# LargeDummyDevice register map
File version: 1.0
Registers are 32-bit, read-write, no defined reset value unless marked. A register's access mark holds for its fields unless they carry their own. Offsets are from the block's base; [hi:lo] are bit positions.

## PERIPHERAL_77
Base 0x4004C000
0x04 REG_1 — Register 1
  [32:30] FIELD_4, [32:30] FIELD_14, [29] FIELD_2, [31:29] FIELD_11, [26:25] FIELD_19, [24:22] FIELD_3, [22] FIELD_21, [23:21] FIELD_6, [18:15] FIELD_13, [16:14] FIELD_15, [13] FIELD_5, [14:13] FIELD_9, [14:11] FIELD_18, [11:10] FIELD_25, [13:9] FIELD_7, [12:9] FIELD_23, [9:8] FIELD_16, [11:7] FIELD_12, [7] FIELD_20, [9:6] FIELD_8, [6:5] FIELD_17, [7:4] FIELD_1, [7:3] FIELD_24, [2:1] FIELD_22, [0] FIELD_10
0x08 REG_2 — Register 2
  [9] FIELD_1
0x0C REG_3 — Register 3
  [33:31] FIELD_2, [30] FIELD_21, [31:29] FIELD_15, [29:28] FIELD_26, [31:27] FIELD_20, [26] FIELD_4, [26:24] FIELD_16, [23] FIELD_14, [23] FIELD_17, [23:19] FIELD_18, [16:14] FIELD_5, [15:13] FIELD_12, [13] FIELD_25, [16:12] FIELD_6, [14:12] FIELD_27, [16:12] FIELD_30, [12:11] FIELD_11, [12:11] FIELD_22, [15:11] FIELD_29, [12:10] FIELD_7, [10:6] FIELD_3, [7:6] FIELD_23, [8:4] FIELD_1, [3:2] FIELD_8, [5:1] FIELD_28, [0] FIELD_9, [0] FIELD_10, [2:0] FIELD_13, [3:0] FIELD_19, [0] FIELD_24
0x10 REG_4 — Register 4
  [33:30] FIELD_1, [29:28] FIELD_2, [28] FIELD_10, [26] FIELD_9, [27:26] FIELD_11, [21] FIELD_6, [17:15] FIELD_8, [11:9] FIELD_4, [6] FIELD_7, [5:4] FIELD_3, [3:1] FIELD_5
0x14 REG_5 — Register 5
  [35:31] FIELD_7, [30:28] FIELD_10, [30:27] FIELD_14, [29:25] FIELD_8, [22] FIELD_15, [20:19] FIELD_1, [21:17] FIELD_6, [17:16] FIELD_2, [14:12] FIELD_13, [11:7] FIELD_5, [9:6] FIELD_4, [7:3] FIELD_11, [2] FIELD_12, [1] FIELD_9, [3:0] FIELD_3
0x18 REG_6 — Register 6
  [30:27] FIELD_4, [27:26] FIELD_1, [22] FIELD_11, [21:20] FIELD_2, [23:20] FIELD_10, [17:13] FIELD_6, [14:12] FIELD_9, [13:10] FIELD_8, [9:8] FIELD_3, [3:2] FIELD_5, [3:1] FIELD_7
0x1C REG_7 — Register 7
  [32:31] FIELD_4, [34:31] FIELD_9, [23] FIELD_17, [25:22] FIELD_1, [23:20] FIELD_7, [23:20] FIELD_11, [19] FIELD_6, [20:18] FIELD_14, [19:18] FIELD_15, [13] FIELD_2, [13] FIELD_8, [15:11] FIELD_10, [11:10] FIELD_5, [9:5] FIELD_13, [4:3] FIELD_3, [3:1] FIELD_12, [0] FIELD_16
0x20 REG_8 — Register 8
  [35:31] FIELD_30, [30] FIELD_15, [32:28] FIELD_9, [29:26] FIELD_20, [29:26] FIELD_24, [28:25] FIELD_26, [27:23] FIELD_16, [26:22] FIELD_8, [19] FIELD_4, [19] FIELD_10, [21:19] FIELD_22, [23:19] FIELD_28, [17] FIELD_27, [18:15] FIELD_17, [16:14] FIELD_23, [15:11] FIELD_2, [15:11] FIELD_5, [15:11] FIELD_7, [11:9] FIELD_13, [12:9] FIELD_31, [8] FIELD_3, [9:8] FIELD_6, [11:8] FIELD_18, [10:8] FIELD_29, [6] FIELD_11, [7:6] FIELD_19, [8:6] FIELD_25, [6:5] FIELD_12, [7:5] FIELD_32, [5:3] FIELD_1, [6:2] FIELD_14, [5:2] FIELD_21
0x24 REG_9 — Register 9
  [25] FIELD_6, [24] FIELD_13, [26:23] FIELD_3, [21] FIELD_5, [22:20] FIELD_4, [16:12] FIELD_7, [14:10] FIELD_2, [11:7] FIELD_9, [11:7] FIELD_11, [8:7] FIELD_12, [7:4] FIELD_1, [4] FIELD_8, [6:4] FIELD_10
0x28 REG_10 — Register 10
  [29:28] FIELD_4, [30:26] FIELD_9, [28:26] FIELD_21, [26] FIELD_27, [25] FIELD_14, [25] FIELD_15, [23] FIELD_22, [25:22] FIELD_1, [24:22] FIELD_17, [25:22] FIELD_24, [21] FIELD_5, [23:20] FIELD_2, [20] FIELD_23, [22:18] FIELD_7, [22:18] FIELD_8, [21:17] FIELD_3, [17] FIELD_12, [14:13] FIELD_10, [16:13] FIELD_28, [14:10] FIELD_18, [12:8] FIELD_11, [10:6] FIELD_6, [9:5] FIELD_13, [7:4] FIELD_16, [7:4] FIELD_19, [6:3] FIELD_25, [5:3] FIELD_26, [2:0] FIELD_20
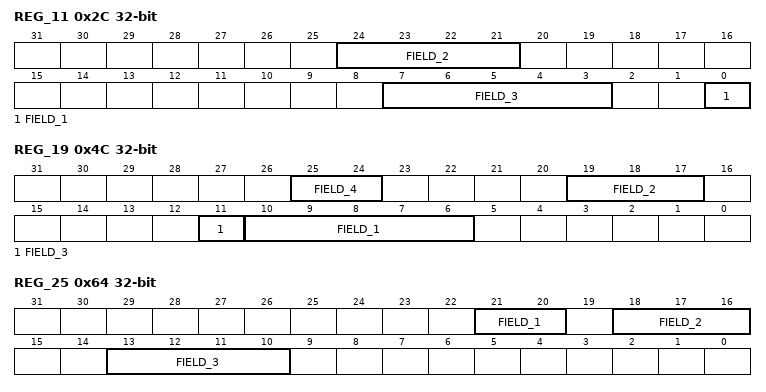
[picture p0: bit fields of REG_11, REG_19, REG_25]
0x2C REG_11 — Register 11
  [24:21] FIELD_2, [7:3] FIELD_3, [0] FIELD_1
0x30 REG_12 — Register 12
  [35:31] FIELD_6, [33:29] FIELD_13, [29:25] FIELD_11, [27:23] FIELD_16, [24:22] FIELD_3, [22] FIELD_21, [24:21] FIELD_1, [24:21] FIELD_5, [23:21] FIELD_18, [19] FIELD_10, [15] FIELD_24, [14] FIELD_12, [14] FIELD_23, [17:13] FIELD_2, [14:11] FIELD_9, [14:11] FIELD_17, [12:10] FIELD_4, [13:10] FIELD_22, [7] FIELD_25, [6:5] FIELD_15, [8:5] FIELD_19, [6:4] FIELD_7, [7:3] FIELD_8, [3] FIELD_14, [4:3] FIELD_20
0x34 REG_13 — Register 13
  [33:31] FIELD_13, [34:30] FIELD_19, [31:29] FIELD_15, [23] FIELD_11, [22:21] FIELD_2, [22:21] FIELD_18, [20:18] FIELD_1, [17:16] FIELD_14, [19:15] FIELD_6, [15:14] FIELD_12, [15:13] FIELD_16, [15:12] FIELD_8, [12:11] FIELD_3, [12:8] FIELD_17, [10:6] FIELD_10, [4:3] FIELD_4, [5:3] FIELD_5, [5:3] FIELD_7, [3:1] FIELD_9
0x38 REG_14 — Register 14
  [32:31] FIELD_16, [34:31] FIELD_24, [30:29] FIELD_2, [31:29] FIELD_30, [30:28] FIELD_8, [29:25] FIELD_6, [26:25] FIELD_32, [26:24] FIELD_17, [25:24] FIELD_31, [27:23] FIELD_5, [23] FIELD_7, [26:22] FIELD_20, [20] FIELD_23, [16:15] FIELD_26, [15:12] FIELD_15, [14:12] FIELD_19, [14:10] FIELD_4, [11:10] FIELD_9, [12:10] FIELD_25, [10:9] FIELD_3, [9] FIELD_11, [12:9] FIELD_14, [9] FIELD_27, [12:8] FIELD_18, [8] FIELD_21, [8:7] FIELD_1, [10:6] FIELD_22, [8:4] FIELD_10, [7:4] FIELD_12, [6:4] FIELD_28, [6:4] FIELD_29, [5:2] FIELD_13
0x3C REG_15 — Register 15
  [32:28] FIELD_3, [17] FIELD_5, [18:14] FIELD_1, [11:7] FIELD_4, [4] FIELD_2
0x40 REG_16 — Register 16
  [35:31] FIELD_7, [34:31] FIELD_11, [30] FIELD_12, [31:29] FIELD_13, [29:25] FIELD_14, [21:17] FIELD_9, [14:13] FIELD_3, [15:13] FIELD_4, [12:11] FIELD_8, [7] FIELD_1, [8:7] FIELD_10, [9:5] FIELD_2, [4] FIELD_6, [3] FIELD_5
0x44 REG_17 — Register 17
  [33:30] FIELD_6, [32:28] FIELD_9, [31:27] FIELD_1, [29:27] FIELD_10, [29:26] FIELD_4, [26:25] FIELD_2, [27:25] FIELD_11, [15] FIELD_3, [11:7] FIELD_7, [9:6] FIELD_8, [1] FIELD_5
0x48 REG_18 — Register 18
  [33:31] FIELD_7, [30] FIELD_3, [27:26] FIELD_2, [26:25] FIELD_9, [26:25] FIELD_26, [26:24] FIELD_8, [27:23] FIELD_4, [24:23] FIELD_6, [27:23] FIELD_12, [25:23] FIELD_16, [26:22] FIELD_10, [24:21] FIELD_1, [22:20] FIELD_27, [20:18] FIELD_19, [18] FIELD_24, [17:16] FIELD_23, [16:15] FIELD_11, [16:13] FIELD_15, [14:13] FIELD_28, [14:12] FIELD_14, [14:10] FIELD_17, [10] FIELD_25, [12:9] FIELD_5, [11:9] FIELD_20, [10:8] FIELD_29, [7:5] FIELD_18, [6:3] FIELD_22, [3:1] FIELD_21, [4:0] FIELD_13
0x4C REG_19 — Register 19
  [25:24] FIELD_4, [19:17] FIELD_2, [11] FIELD_3, [10:6] FIELD_1
0x50 REG_20 — Register 20
  [35:31] FIELD_3, [31:29] FIELD_11, [29] FIELD_15, [29:28] FIELD_18, [32:28] FIELD_22, [26:25] FIELD_8, [24] FIELD_10, [22] FIELD_19, [24:21] FIELD_13, [23:21] FIELD_14, [25:21] FIELD_30, [24:20] FIELD_17, [20:19] FIELD_6, [21:17] FIELD_23, [15:13] FIELD_2, [17:13] FIELD_29, [12] FIELD_1, [12] FIELD_4, [11] FIELD_24, [14:10] FIELD_27, [10] FIELD_28, [7] FIELD_5, [11:7] FIELD_12, [10:6] FIELD_21, [9:6] FIELD_26, [5] FIELD_31, [8:4] FIELD_9, [3] FIELD_20, [4:2] FIELD_16, [3:2] FIELD_25, [4:2] FIELD_32, [3:1] FIELD_7
0x54 REG_21 — Register 21
  [35:31] FIELD_17, [31:30] FIELD_11, [30] FIELD_12, [31:27] FIELD_3, [26:22] FIELD_19, [22:21] FIELD_7, [21:18] FIELD_2, [19:17] FIELD_6, [17] FIELD_21, [20:16] FIELD_15, [16:13] FIELD_1, [17:13] FIELD_13, [13] FIELD_14, [17:13] FIELD_16, [12:11] FIELD_9, [10:8] FIELD_10, [10:7] FIELD_4, [8:7] FIELD_18, [6] FIELD_20, [8:4] FIELD_5, [3] FIELD_8
0x58 REG_22 — Register 22
  [11:9] FIELD_1
0x5C REG_23 — Register 23
  [34:30] FIELD_9, [27:26] FIELD_8, [28:25] FIELD_2, [27:23] FIELD_12, [27:23] FIELD_17, [25:21] FIELD_3, [24:21] FIELD_16, [20:19] FIELD_5, [20:19] FIELD_6, [15:14] FIELD_4, [13] FIELD_10, [15:12] FIELD_11, [13:12] FIELD_14, [14:10] FIELD_15, [12:8] FIELD_13, [11:7] FIELD_1, [6] FIELD_18, [4:1] FIELD_7
0x60 REG_24 — Register 24
  [33:30] FIELD_2, [9:5] FIELD_1
0x64 REG_25 — Register 25
  [21:20] FIELD_1, [18:16] FIELD_2, [13:10] FIELD_3
0x68 REG_26 — Register 26
  [28:26] FIELD_9, [25:24] FIELD_23, [28:24] FIELD_25, [25:23] FIELD_5, [20] FIELD_2, [24:20] FIELD_3, [16] FIELD_26, [18:15] FIELD_8, [18:14] FIELD_10, [16:14] FIELD_13, [14:13] FIELD_1, [13] FIELD_17, [15:12] FIELD_12, [12] FIELD_15, [15:11] FIELD_24, [14:11] FIELD_27, [14:10] FIELD_7, [12:8] FIELD_16, [8:7] FIELD_6, [10:6] FIELD_11, [7:5] FIELD_4, [5:3] FIELD_19, [3] FIELD_20, [5:3] FIELD_21, [4:2] FIELD_18, [0] FIELD_14, [4:0] FIELD_22
0x6C REG_27 — Register 27
  [30:28] FIELD_9, [30:28] FIELD_14, [29:26] FIELD_2, [28:25] FIELD_1, [28:25] FIELD_4, [22:19] FIELD_16, [20:19] FIELD_17, [21:17] FIELD_11, [15] FIELD_18, [14] FIELD_5, [16:14] FIELD_7, [14:13] FIELD_3, [16:12] FIELD_13, [12:11] FIELD_15, [14:10] FIELD_6, [13:10] FIELD_12, [10:9] FIELD_10, [3:0] FIELD_8
0x70 REG_28 — Register 28
  [35:31] FIELD_6, [29:27] FIELD_10, [27:24] FIELD_3, [25:22] FIELD_12, [22:19] FIELD_2, [20:19] FIELD_11, [20:18] FIELD_1, [18:16] FIELD_7, [17:16] FIELD_8, [15:14] FIELD_4, [10:7] FIELD_9, [7:6] FIELD_15, [7:5] FIELD_5, [3:1] FIELD_13, [3:0] FIELD_14
0x74 REG_29 — Register 29
  [25:24] FIELD_3, [25:23] FIELD_9, [18:16] FIELD_8, [19:15] FIELD_10, [12] FIELD_2, [14:10] FIELD_13, [12:8] FIELD_6, [10:7] FIELD_1, [8:7] FIELD_11, [4] FIELD_4, [3] FIELD_7, [7:3] FIELD_12, [3:1] FIELD_5
0x78 REG_30 — Register 30
  [29:28] FIELD_12, [27] FIELD_2, [30:27] FIELD_5, [29:26] FIELD_14, [27:24] FIELD_6, [26:24] FIELD_24, [23:22] FIELD_13, [22:18] FIELD_17, [20:16] FIELD_9, [16] FIELD_20, [17:14] FIELD_16, [14:13] FIELD_10, [17:13] FIELD_23, [12:11] FIELD_18, [12:10] FIELD_8, [11:9] FIELD_15, [13:9] FIELD_25, [11:8] FIELD_3, [9:8] FIELD_11, [9:7] FIELD_7, [5:3] FIELD_22, [5:1] FIELD_4, [2:1] FIELD_19, [2:1] FIELD_21, [0] FIELD_1
0x7C REG_31 — Register 31
  [32:30] FIELD_4, [33:30] FIELD_24, [32:30] FIELD_25, [28] FIELD_10, [27] FIELD_11, [30:26] FIELD_1, [29:26] FIELD_14, [29:25] FIELD_30, [24] FIELD_23, [26:23] FIELD_13, [25:23] FIELD_15, [26:22] FIELD_22, [24:20] FIELD_7, [19] FIELD_18, [19:18] FIELD_12, [17] FIELD_20, [18:16] FIELD_28, [15:13] FIELD_9, [15:11] FIELD_5, [12:11] FIELD_8, [14:10] FIELD_21, [11:8] FIELD_26, [4] FIELD_19, [8:4] FIELD_27, [7:3] FIELD_16, [3] FIELD_29, [2:1] FIELD_6, [1] FIELD_17, [1:0] FIELD_2, [1:0] FIELD_3
0x80 REG_32 — Register 32
  [31] FIELD_1, [34:30] FIELD_16, [31:29] FIELD_4, [31:29] FIELD_15, [30:26] FIELD_12, [26:24] FIELD_10, [23:21] FIELD_14, [22:20] FIELD_11, [23:19] FIELD_5, [21:17] FIELD_3, [18:15] FIELD_6, [9:7] FIELD_13, [7:6] FIELD_7, [7:6] FIELD_8, [8:4] FIELD_2, [1] FIELD_9
0x84 REG_33 — Register 33
  [13:11] FIELD_1
0x88 REG_34 — Register 34
  [31:28] FIELD_1, [26:22] FIELD_5, [22:20] FIELD_2, [22:18] FIELD_4, [14:12] FIELD_3, [8:5] FIELD_6
0x8C REG_35 — Register 35
  [31:30] FIELD_4, [29:26] FIELD_13, [28:25] FIELD_10, [26:25] FIELD_12, [27:24] FIELD_16, [27:23] FIELD_6, [23:22] FIELD_11, [20] FIELD_2, [23:19] FIELD_14, [20:19] FIELD_24, [18] FIELD_3, [17] FIELD_18, [20:16] FIELD_20, [19:16] FIELD_22, [17:15] FIELD_23, [18:14] FIELD_9, [12] FIELD_21, [13:9] FIELD_7, [10:8] FIELD_15, [7:6] FIELD_5, [9:6] FIELD_19, [2] FIELD_8, [3:1] FIELD_1, [1:0] FIELD_17
0x90 REG_36 — Register 36
  [35:31] FIELD_14, [32:30] FIELD_2, [30:29] FIELD_16, [28] FIELD_18, [30:27] FIELD_13, [30:26] FIELD_15, [25] FIELD_1, [25:23] FIELD_17, [25:23] FIELD_20, [26:22] FIELD_4, [22:21] FIELD_29, [23:20] FIELD_3, [22:20] FIELD_5, [20] FIELD_19, [21:20] FIELD_27, [18:17] FIELD_7, [17:16] FIELD_12, [15:13] FIELD_22, [15:11] FIELD_6, [12:9] FIELD_10, [10:9] FIELD_26, [7:6] FIELD_24, [6:5] FIELD_23, [5] FIELD_25, [6:5] FIELD_28, [4:2] FIELD_8, [5:1] FIELD_11, [3:1] FIELD_21, [3:0] FIELD_9
